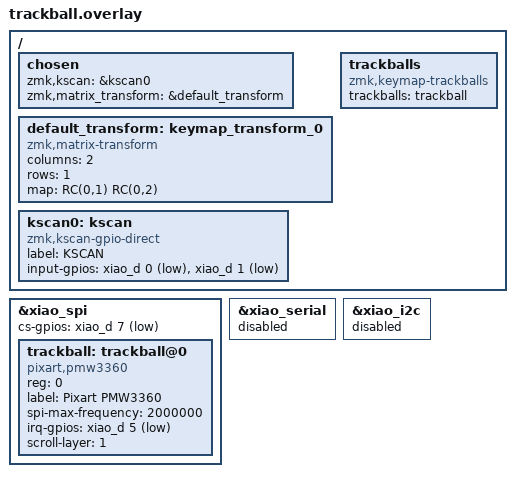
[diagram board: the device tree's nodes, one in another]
#include <dt-bindings/zmk/matrix_transform.h>

&xiao_spi {
    status = "okay";
    cs-gpios = <&xiao_d 7 GPIO_ACTIVE_LOW>;

    trackball: trackball@0 {
        status = "okay";
        compatible = "pixart,pmw3360";
        reg = <0>;
        label = "Pixart PMW3360";
        spi-max-frequency = <2000000>;
        irq-gpios = <&xiao_d 5 (GPIO_ACTIVE_LOW | GPIO_PULL_UP)>;
        scroll-layer = <1>;
    };

};

&xiao_serial { status = "disabled"; };
&xiao_i2c { status = "disabled"; };

/ {
    chosen {
        zmk,kscan = &kscan0;
        zmk,matrix_transform = &default_transform;
    };

    default_transform: keymap_transform_0 {
        compatible = "zmk,matrix-transform";
        columns = <2>;
        rows = <1>;
        map = <RC(0,1) RC(0,2)>;
    };

    kscan0: kscan {
        compatible = "zmk,kscan-gpio-direct";
        label = "KSCAN";

        input-gpios =
            <&xiao_d 0 (GPIO_ACTIVE_LOW | GPIO_PULL_UP)>,
            <&xiao_d 1 (GPIO_ACTIVE_LOW | GPIO_PULL_UP)>;

    };

    trackballs {
        compatible = "zmk,keymap-trackballs";
        trackballs = <&trackball>;
    };

};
